# CPSW0_NUSS register map
Vendor: Texas Instruments
Peripheral module from a debugger description file (folder am62P).
Registers are 32-bit, read-write, reset 0x0 unless marked. A register's access mark holds for its fields unless they carry their own. Offsets are as the file gives them; lines under a group give offsets from that group; [hi:lo] are bit positions; {n}, {i} and the like mark numbered series; 'fields as' and 'values as' point back to an identical list; <NAME> marks a mode.

## CPSW0_NUSS
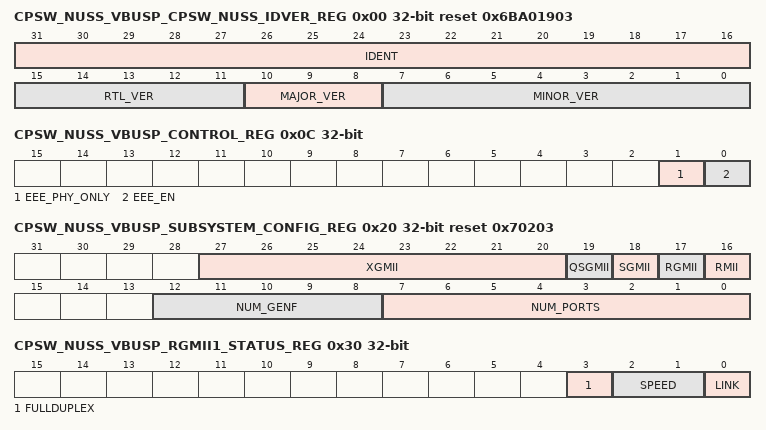
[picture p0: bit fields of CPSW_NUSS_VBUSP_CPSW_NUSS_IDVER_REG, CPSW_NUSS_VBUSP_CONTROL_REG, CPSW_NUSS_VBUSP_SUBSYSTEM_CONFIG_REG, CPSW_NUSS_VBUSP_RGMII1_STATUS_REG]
0x00 CPSW_NUSS_VBUSP_CPSW_NUSS_IDVER_REG ro reset 0x6BA01903 — ID Version Register
  [31:16] IDENT — Identification value
  [15:11] RTL_VER — RTL version value
  [10:8] MAJOR_VER — Major version value
  [7:0] MINOR_VER — Minor version value
0x04 CPSW_NUSS_VBUSP_SYNCE_COUNT_REG — SyncE Count Register
  [31:0] SYNCE_CNT — Sync E Count Value
0x08 CPSW_NUSS_VBUSP_SYNCE_MUX_REG — SyncE Mux Register
  [5:0] SYNCE_SEL — Sync E Select Value
0x0C CPSW_NUSS_VBUSP_CONTROL_REG — Control Register
  [1] EEE_PHY_ONLY — Energy Efficient Enable Phy Only Mode: 0=The low power indicate state includes gating off the CPPI_GCLK to the CPSW, 1=The low power indicate state does not gate the clock to the CPSW
  [0] EEE_EN — Energy Efficient Ethernet Enable: 0=EEE is disabled, 1=EEE is enabled
0x10 CPSW_NUSS_VBUSP_SGMII_NON_FIBER_MODE_REG reset 0x3 — SGMII NON FIBER Mode Register
  [1:0] SGMII_NON_FIBER_MODE — This register bit goes to the CPSGMII mode input only
0x14 CPSW_NUSS_VBUSP_SERDES_RESET_ISO_REG — SyncE Mux Register
  [1:0] SERDES_RESET_ISO — These bits control whether the SERDES ignores the hard reset for isolation or not
0x1C CPSW_NUSS_VBUSP_SUBSSYSTEM_STATUS_REG ro — Subsystem Status Register
  [0] EEE_CLKSTOP_ACK — Energy Efficient Ethernet clockstop acknowledge from CPSW
0x20 CPSW_NUSS_VBUSP_SUBSYSTEM_CONFIG_REG ro reset 0x70203 — Subsystem Configuration Register
  [27:20] XGMII — The Number of XGMII Ports included in the CPSW_NUSS
  [19] QSGMII — QSGMII is included in the CPSW_NUSS
  [18] SGMII — SGMII is included in the CPSW_NUSS
  [17] RGMII — RGMII is included in the CPSW_NUSS
  [16] RMII — RMII is included in the CPSW_NUSS
  [12:8] NUM_GENF — The number of CPTS GENF outputs
  [7:0] NUM_PORTS — The total number of ports including the host port 0
0x30 CPSW_NUSS_VBUSP_RGMII1_STATUS_REG ro — RGMII1 Status Register
  [3] FULLDUPLEX — Rgmii1 full dulex: 0=Half-duplex, 1=Full-duplex
  [2:1] SPEED — Rgmii1 speed: 00=10Mbps, 01=100Mbps, 10=1000Mbps, 11=reserved
  [0] LINK — Rgmii1 link indicator: 0=Link is down, 1=Link is up
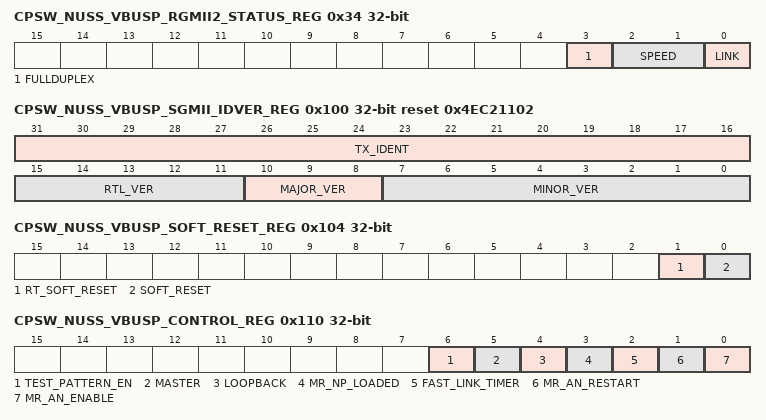
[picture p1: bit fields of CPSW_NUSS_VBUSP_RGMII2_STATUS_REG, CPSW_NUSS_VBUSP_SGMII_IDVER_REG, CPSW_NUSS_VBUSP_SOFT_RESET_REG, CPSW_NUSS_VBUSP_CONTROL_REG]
0x34 CPSW_NUSS_VBUSP_RGMII2_STATUS_REG ro — RGMII2 Status Register
  [3] FULLDUPLEX — Rgmii2 full dulex: 0=Half-duplex, 1=Full-duplex
  [2:1] SPEED — Rgmii2 speed: 00=10Mbps, 01=100Mbps, 10=1000Mbps, 11=reserved
  [0] LINK — Rgmii2 link indicator: 0=Link is down, 1=Link is up
0x100 CPSW_NUSS_VBUSP_SGMII_IDVER_REG ro reset 0x4EC21102 — SGMII IDVER register
  [31:16] TX_IDENT — MODULE value
  [15:11] RTL_VER — RTL version value
  [10:8] MAJOR_VER — Major version value
  [7:0] MINOR_VER — Minor version value
0x104 CPSW_NUSS_VBUSP_SOFT_RESET_REG — SGMII Soft Reset Register
  [1] RT_SOFT_RESET — Transmit and receive software reset
  [0] SOFT_RESET — Software reset
0x110 CPSW_NUSS_VBUSP_CONTROL_REG — SGMII Control Register
  [6] TEST_PATTERN_EN — Test pattern enable
  [5] MASTER — Controller mode
  [4] LOOPBACK — Loopback mode
  [3] MR_NP_LOADED — Next page loaded
  [2] FAST_LINK_TIMER
  [1] MR_AN_RESTART — Auto-negotiation restart
  [0] MR_AN_ENABLE — Auto-negotiation enable
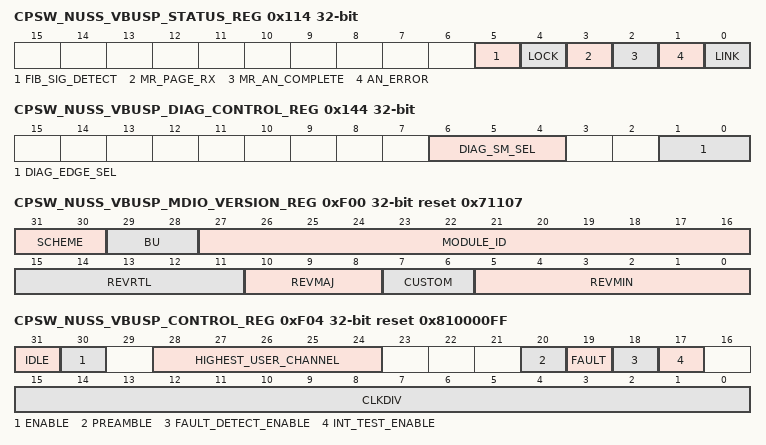
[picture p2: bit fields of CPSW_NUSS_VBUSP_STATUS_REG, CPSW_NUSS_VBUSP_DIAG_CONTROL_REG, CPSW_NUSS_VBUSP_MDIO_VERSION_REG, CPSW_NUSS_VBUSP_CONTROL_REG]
0x114 CPSW_NUSS_VBUSP_STATUS_REG ro — SGMII Status Register
  [5] FIB_SIG_DETECT — Fiber signal detect
  [4] LOCK
  [3] MR_PAGE_RX — Next page received
  [2] MR_AN_COMPLETE — Auto-negotiation complete
  [1] AN_ERROR — Auto-negotiation error
  [0] LINK — Link indicator
0x118 CPSW_NUSS_VBUSP_MR_ADV_ABILITY_REG — SGMII MR Advertized Ability Register
  [15:0] MR_ADV_ABILITY — Advertised ability
0x11C CPSW_NUSS_VBUSP_MR_NP_TX_REG — SGMII Next Pate Transmit Register
  [15:0] MR_NP_TX — Next page transmit
0x120 CPSW_NUSS_VBUSP_MR_LP_ADV_ABILITY_REG ro — SGMII Link Partner Advertized Ability Register
  [15:0] MR_LP_ADV_ABILITY — Link partner advertised ability
0x124 CPSW_NUSS_VBUSP_MR_LP_NP_RX_REG ro — SGMII Link Partner Next Page Receive Register
  [15:0] MR_LP_NP_RX — Link Partner Next Page Received
0x140 CPSW_NUSS_VBUSP_DIAG_CLEAR_REG — SGMII Diagnostics Clear Register
  [0] DIAG_CLEAR — Diagnostics clear
0x144 CPSW_NUSS_VBUSP_DIAG_CONTROL_REG — SGMII Diagnostics Control Register
  [6:4] DIAG_SM_SEL — Diagnostic select
  [1:0] DIAG_EDGE_SEL — Diagnostics hold signals edge select
0x148 CPSW_NUSS_VBUSP_DIAG_STATUS_REG ro — SGMII Diagnostics Status Register
  [15:0] DIAG_STATUS — Diagnostics status
0xF00 CPSW_NUSS_VBUSP_MDIO_VERSION_REG ro reset 0x71107 — MDIO Version Register
  [31:30] SCHEME
  [29:28] BU
  [27:16] MODULE_ID
  [15:11] REVRTL — RTL version
  [10:8] REVMAJ — Major version
  [7:6] CUSTOM — Custom version
  [5:0] REVMIN — Minor version
0xF04 CPSW_NUSS_VBUSP_CONTROL_REG access per field reset 0x810000FF — MDIO Control Register
  [31] IDLE ro — MDIO state machine idle
  [30] ENABLE rw — Enable control
  [28:24] HIGHEST_USER_CHANNEL ro
  [20] PREAMBLE rw — Preamble disable
  [19] FAULT rw — Fault indicator
  [18] FAULT_DETECT_ENABLE rw
  [17] INT_TEST_ENABLE rw — Interrupt test enable
  [15:0] CLKDIV rw — Clock divider
0xF08 CPSW_NUSS_VBUSP_ALIVE_REG — MDIO Alive Register
  [31:0] ALIVE — MDIO alive
0xF0C CPSW_NUSS_VBUSP_LINK_REG ro — MDIO Link Register
  [31:0] LINK — MDIO link state
0xF10 CPSW_NUSS_VBUSP_LINK_INT_RAW_REG — MDIO Link Interrupt Raw Register
  [1:0] LINKINTRAW — MDIO link change event raw value
0xF14 CPSW_NUSS_VBUSP_LINK_INT_MASKED_REG — MDIO Link Interrupt Masked Register
  [1:0] LINKINTMASKED — MDIO link change interrupt masked value
0xF18 CPSW_NUSS_VBUSP_LINK_INT_MASK_SET_REG — MDIO Link Interrupt Mask Set Register
  [0] LINKINTMASKSET — MDIO link interrupt mask set
0xF1C CPSW_NUSS_VBUSP_LINK_INT_MASK_CLEAR_REG — MDIO Link Interrupt Mask Clear Register
  [0] LINKINTMASKCLR — MDIO link interrupt mask clear
0xF20 CPSW_NUSS_VBUSP_USER_INT_RAW_REG — MDIO User Interrupt Raw Register
  [1:0] USERINTRAW — User interrupt raw
0xF24 CPSW_NUSS_VBUSP_USER_INT_MASKED_REG — MDIO User Interrupt Masked Register
  [1:0] USERINTMASKED — User interrupt masked
0xF28 CPSW_NUSS_VBUSP_USER_INT_MASK_SET_REG — MDIO User Interrupt Mask Set Register
  [1:0] USERINTMASKSET — MDIO user interrupt mask set
0xF2C CPSW_NUSS_VBUSP_USER_INT_MASK_CLEAR_REG — MDIO User Interrupt Mask Clear Register
  [1:0] USERINTMASKCLR — MDIO user interrupt mask clear
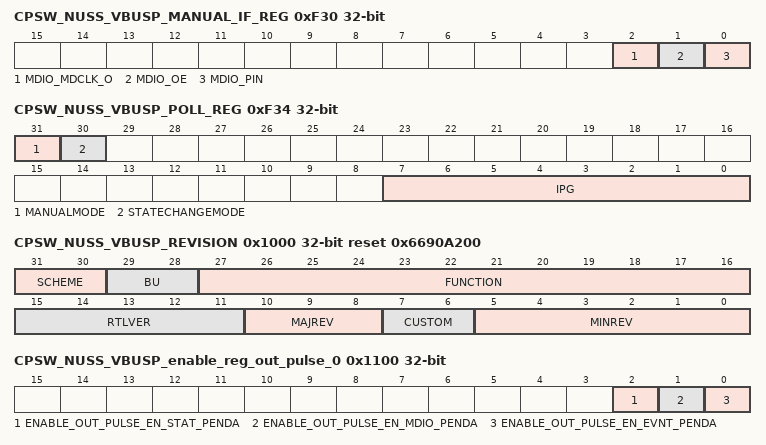
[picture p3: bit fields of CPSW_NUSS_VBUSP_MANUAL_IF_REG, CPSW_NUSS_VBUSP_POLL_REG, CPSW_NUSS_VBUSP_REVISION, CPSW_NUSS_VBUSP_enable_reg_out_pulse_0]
0xF30 CPSW_NUSS_VBUSP_MANUAL_IF_REG — MDIO Manual Interface Register
  [2] MDIO_MDCLK_O — MDIO Clock Output
  [1] MDIO_OE — MDIO Output Enable
  [0] MDIO_PIN
0xF34 CPSW_NUSS_VBUSP_POLL_REG — MDIO Poll Register
  [31] MANUALMODE — MDIO Manual Mode
  [30] STATECHANGEMODE — MDIO State Change Mode
  [7:0] IPG — MDIO IPG
0xF38 CPSW_NUSS_VBUSP_POLL_EN_REG reset 0xFFFFFFFF — MDIO Poll Enable Register
  [31:0] POLL_EN — MDIO Poll Enable
0xF3C CPSW_NUSS_VBUSP_CLAUS45_REG — MDIO Clause45 Register
  [31:0] CLAUSE45 — MDIO Clause 45
0xF40 CPSW_NUSS_VBUSP_USER_ADDR0_REG — MDIO Address 0 Register
  [15:0] USER_ADDR0 — MDIO USER Address 0
0xF44 CPSW_NUSS_VBUSP_USER_ADDR1_REG — MDIO Address 1 Register
  [15:0] USER_ADDR1 — MDIO USER Address 1
0x1000 CPSW_NUSS_VBUSP_REVISION ro reset 0x6690A200 — Revision Register
  [31:30] SCHEME
  [29:28] BU
  [27:16] FUNCTION — Module ID
  [15:11] RTLVER — RTL revisions
  [10:8] MAJREV — Major revision
  [7:6] CUSTOM — Custom revision
  [5:0] MINREV — Minor revision
0x1010 CPSW_NUSS_VBUSP_eoi_reg — End of Interrupt Register
  [7:0] EOI_VECTOR — End of Interrupt Vector
0x1014 CPSW_NUSS_VBUSP_intr_vector_reg ro — Interrupt Vector Register
  [31:0] INTR_VECTOR
0x1100 CPSW_NUSS_VBUSP_enable_reg_out_pulse_0 access not given — Enable Register 0
  [2] ENABLE_OUT_PULSE_EN_STAT_PENDA — Enable Set for out_pulse_en_stat_penda (access R/W1TS)
  [1] ENABLE_OUT_PULSE_EN_MDIO_PENDA — Enable Set for out_pulse_en_mdio_penda (access R/W1TS)
  [0] ENABLE_OUT_PULSE_EN_EVNT_PENDA — Enable Set for out_pulse_en_evnt_penda (access R/W1TS)
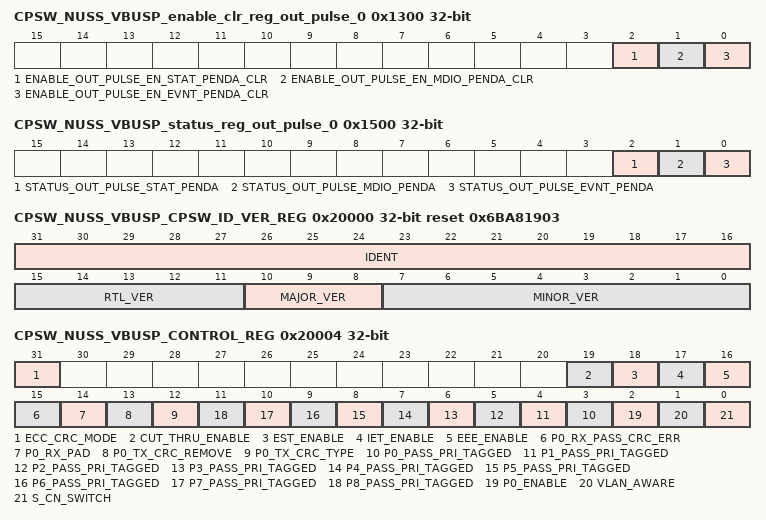
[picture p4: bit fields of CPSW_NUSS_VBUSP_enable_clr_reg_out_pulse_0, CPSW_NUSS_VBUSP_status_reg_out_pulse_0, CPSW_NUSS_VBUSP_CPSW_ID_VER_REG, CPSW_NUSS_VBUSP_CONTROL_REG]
0x1300 CPSW_NUSS_VBUSP_enable_clr_reg_out_pulse_0 access not given — Enable Clear Register 0
  [2] ENABLE_OUT_PULSE_EN_STAT_PENDA_CLR — Enable Clear for out_pulse_en_stat_penda (access R/W1TC)
  [1] ENABLE_OUT_PULSE_EN_MDIO_PENDA_CLR — Enable Clear for out_pulse_en_mdio_penda (access R/W1TC)
  [0] ENABLE_OUT_PULSE_EN_EVNT_PENDA_CLR — Enable Clear for out_pulse_en_evnt_penda (access R/W1TC)
0x1500 CPSW_NUSS_VBUSP_status_reg_out_pulse_0 ro — Status Register 0
  [2] STATUS_OUT_PULSE_STAT_PENDA — Status for out_pulse_en_stat_penda
  [1] STATUS_OUT_PULSE_MDIO_PENDA — Status for out_pulse_en_mdio_penda
  [0] STATUS_OUT_PULSE_EVNT_PENDA — Status for out_pulse_en_evnt_penda
0x1A80 CPSW_NUSS_VBUSP_intr_vector_reg_out_pulse ro — Interrupt Vector for out_pulse
  [31:0] INTR_VECTOR_OUT_PULSE — Interrupt Vector
0x20000 CPSW_NUSS_VBUSP_CPSW_ID_VER_REG ro reset 0x6BA81903 — CPSW ID Version
  [31:16] IDENT — Identification Value
  [15:11] RTL_VER — RTL Version Value
  [10:8] MAJOR_VER — Major Version Value
  [7:0] MINOR_VER — Minor Version Value
0x20004 CPSW_NUSS_VBUSP_CONTROL_REG — CPSW Switch Control
  [31] ECC_CRC_MODE
  [19] CUT_THRU_ENABLE
  [18] EST_ENABLE — Intersperced Express Traffic enable
  [17] IET_ENABLE — Intersperced Express Traffic enable
  [16] EEE_ENABLE — Energy Efficient Ethernet enable
  [15] P0_RX_PASS_CRC_ERR — Port 0 Pass Received CRC errors
  [14] P0_RX_PAD — Port 0 Receive Short Packet Pad
  [13] P0_TX_CRC_REMOVE — Port 0 Transmit CRC remove
  [12] P0_TX_CRC_TYPE — Port 0 Transmit CRC Type
  [n+3] P{n}_PASS_PRI_TAGGED (n=0..8) — Port {n} Pass Priority Tagged
  [2] P0_ENABLE — Port 0 Enable
  [1] VLAN_AWARE — VLAN Aware Mode
  [0] S_CN_SWITCH — VLAN Aware Mode
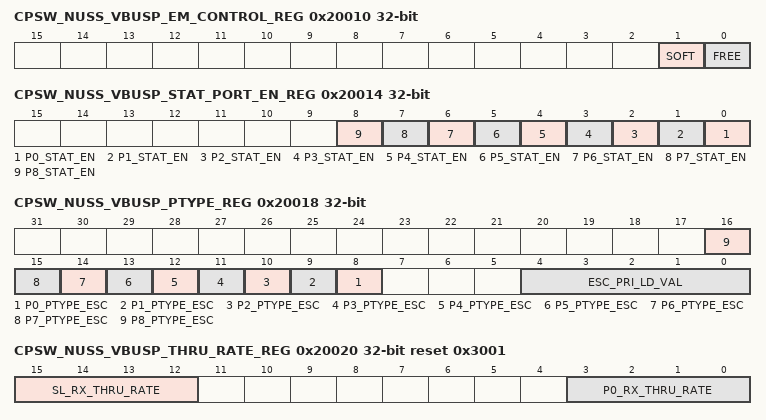
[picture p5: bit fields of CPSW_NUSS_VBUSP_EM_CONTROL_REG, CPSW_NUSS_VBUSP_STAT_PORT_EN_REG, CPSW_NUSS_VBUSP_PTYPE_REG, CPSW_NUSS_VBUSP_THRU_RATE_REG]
0x20010 CPSW_NUSS_VBUSP_EM_CONTROL_REG — CPSW Emulation Control
  [1] SOFT — Emulation Soft Bit
  [0] FREE — Emulation Free Bit
0x20014 CPSW_NUSS_VBUSP_STAT_PORT_EN_REG — CPSW Statistics Port Enable
  [n] P{n}_STAT_EN (n=0..8) — Port {n} Statistics Enable
0x20018 CPSW_NUSS_VBUSP_PTYPE_REG — CPSW Transmit Priority Type
  [n+8] P{n}_PTYPE_ESC (n=0..8) — Port {n} Priority Type Escalate
  [4:0] ESC_PRI_LD_VAL — Escalate Priority Load Value
0x2001C CPSW_NUSS_VBUSP_SOFT_IDLE_REG — CPSW Software Idle
  [0] SOFT_IDLE — Software Idle
0x20020 CPSW_NUSS_VBUSP_THRU_RATE_REG reset 0x3001 — CPSW Thru Rate
  [15:12] SL_RX_THRU_RATE — Switch FIFO receive through rate
  [3:0] P0_RX_THRU_RATE — CPPI FIFO receive through rate
0x20024 CPSW_NUSS_VBUSP_GAP_THRESH_REG reset 0xB — CPSW Transmit FIFO Short Gap Threshold
  [4:0] GAP_THRESH — Short Gap Threshold
0x2002C CPSW_NUSS_VBUSP_EEE_PRESCALE_REG — CPSW Energy Efficient Ethernet Prescale Value
  [11:0] EEE_PRESCALE — Energy Efficient Ethernet Pre-scale count load value
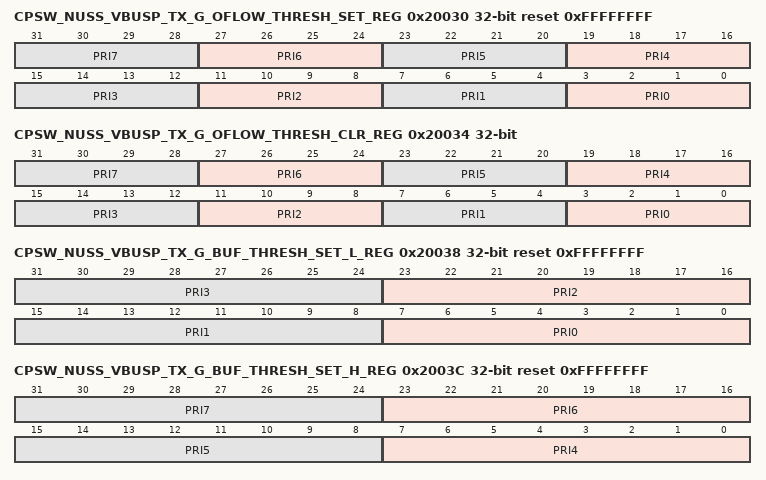
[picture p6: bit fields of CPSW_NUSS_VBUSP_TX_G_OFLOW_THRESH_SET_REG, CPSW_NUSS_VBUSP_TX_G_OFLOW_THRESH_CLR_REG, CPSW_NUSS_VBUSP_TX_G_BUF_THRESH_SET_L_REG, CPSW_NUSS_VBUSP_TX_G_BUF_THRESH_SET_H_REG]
0x20030 CPSW_NUSS_VBUSP_TX_G_OFLOW_THRESH_SET_REG reset 0xFFFFFFFF — CPSW PFC Tx Global Out Flow Threshold Set
  [4n+3:4n] PRI{n} (n=0..7) — Priority Based Flow Control Global Outflow Usage Threshold for Pri {n}
0x20034 CPSW_NUSS_VBUSP_TX_G_OFLOW_THRESH_CLR_REG — CPSW PFC Tx Global Out Flow Threshold Clear
  fields as CPSW_NUSS_VBUSP_TX_G_OFLOW_THRESH_SET_REG
0x20038 CPSW_NUSS_VBUSP_TX_G_BUF_THRESH_SET_L_REG reset 0xFFFFFFFF — CPSW PFC Global Tx Buffer Threshold Set Low
  [8n+7:8n] PRI{n} (n=0..3) — Priority Based Flow Control Global Buffer Usage Threshold for Priority {n}
0x2003C CPSW_NUSS_VBUSP_TX_G_BUF_THRESH_SET_H_REG reset 0xFFFFFFFF — CPSW PFC Global Tx Buffer Threshold Set High
  [8n-25:8n-32] PRI{n} (n=4..7) — Priority Based Flow Control Global Buffer Usage Threshold for Priority {n}
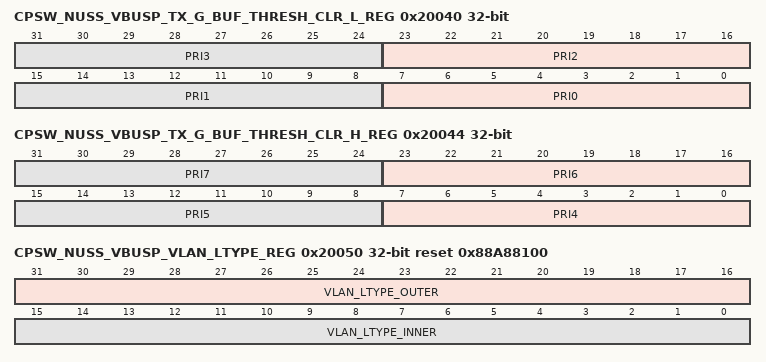
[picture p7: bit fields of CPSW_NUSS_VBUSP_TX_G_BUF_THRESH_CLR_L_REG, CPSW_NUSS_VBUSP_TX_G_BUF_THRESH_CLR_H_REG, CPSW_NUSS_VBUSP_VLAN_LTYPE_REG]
0x20040 CPSW_NUSS_VBUSP_TX_G_BUF_THRESH_CLR_L_REG — CPSW PFC Global Tx Buffer Threshold Clear Low
  fields as CPSW_NUSS_VBUSP_TX_G_BUF_THRESH_SET_L_REG
0x20044 CPSW_NUSS_VBUSP_TX_G_BUF_THRESH_CLR_H_REG — CPSW PFC Global Tx Buffer Threshold Clear High
  fields as CPSW_NUSS_VBUSP_TX_G_BUF_THRESH_SET_H_REG
0x20050 CPSW_NUSS_VBUSP_VLAN_LTYPE_REG reset 0x88A88100 — VLAN Length/type
  [31:16] VLAN_LTYPE_OUTER — Outer VLAN LType
  [15:0] VLAN_LTYPE_INNER — Inner VLAN LType
0x20054 CPSW_NUSS_VBUSP_EST_TS_DOMAIN_REG — Enhanced Scheduled Traffic Host Event Domain
  [7:0] EST_TS_DOMAIN
0x20058 CPSW_NUSS_VBUSP_CUT_THRESHOLD_REG — Cut-thru Threshold
  [3:0] CUT_THRESH
0x2005C CPSW_NUSS_VBUSP_FREQUENCY_REG — CPSW CPPI_CLK Frequency in Mhz
  [9:0] CUT_THRESH
0x20060 CPSW_NUSS_VBUSP_IET_HOLD_CNT_LD_VAL_REG reset 0x64 — IET Hold Count Load Value for cut thru packets
  [7:0] IET_HOLD_CNT_LD_VAL
{0x20100+4i} CPSW_NUSS_VBUSP_TX_PRI{i}_MAXLEN_REG reset 0x7E8 (i=0..7) — Transmit Priority {i} Maximum Length
  [13:0] TX_PRI{i}_MAXLEN
